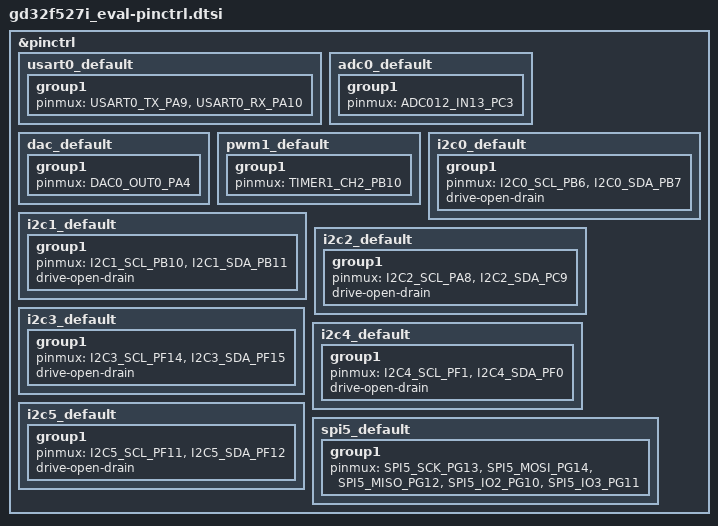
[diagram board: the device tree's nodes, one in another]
/*
 * Copyright (c) 2025 GigaDevice Semiconductor Inc.
 *
 * SPDX-License-Identifier: Apache-2.0
 */

#include <dt-bindings/pinctrl/gd32f527i(m-s)xx-pinctrl.h>

&pinctrl {
	usart0_default: usart0_default {
		group1 {
			pinmux = <USART0_TX_PA9>, <USART0_RX_PA10>;
		};
	};

	adc0_default: adc0_default {
		group1 {
			pinmux = <ADC012_IN13_PC3>;
		};
	};

	dac_default: dac_default {
		group1 {
			pinmux = <DAC0_OUT0_PA4>;
		};
	};

	pwm1_default: pwm1_default {
		group1 {
			pinmux = <TIMER1_CH2_PB10>;
		};
	};

	i2c0_default: i2c0_default {
		group1 {
			pinmux = <I2C0_SCL_PB6>, <I2C0_SDA_PB7>;
			drive-open-drain;
		};
	};

	i2c1_default: i2c1_default {
		group1 {
			pinmux = <I2C1_SCL_PB10>, <I2C1_SDA_PB11>;
			drive-open-drain;
		};
	};

	i2c2_default: i2c2_default {
		group1 {
			pinmux = <I2C2_SCL_PA8>, <I2C2_SDA_PC9>;
			drive-open-drain;
		};
	};

	i2c3_default: i2c3_default {
		group1 {
			pinmux = <I2C3_SCL_PF14>, <I2C3_SDA_PF15>;
			drive-open-drain;
		};
	};

	i2c4_default: i2c4_default {
		group1 {
			pinmux = <I2C4_SCL_PF1>, <I2C4_SDA_PF0>;
			drive-open-drain;
		};
	};

	i2c5_default: i2c5_default {
		group1 {
			pinmux = <I2C5_SCL_PF11>, <I2C5_SDA_PF12>;
			drive-open-drain;
		};
	};

	spi5_default: spi5_default {
		group1 {
			pinmux = <SPI5_SCK_PG13>, <SPI5_MOSI_PG14>,
				 <SPI5_MISO_PG12>,
				 /* Use pinmux to pullup pg10 and pg11. */
				 <SPI5_IO2_PG10>, <SPI5_IO3_PG11>;
		};
	};
};
